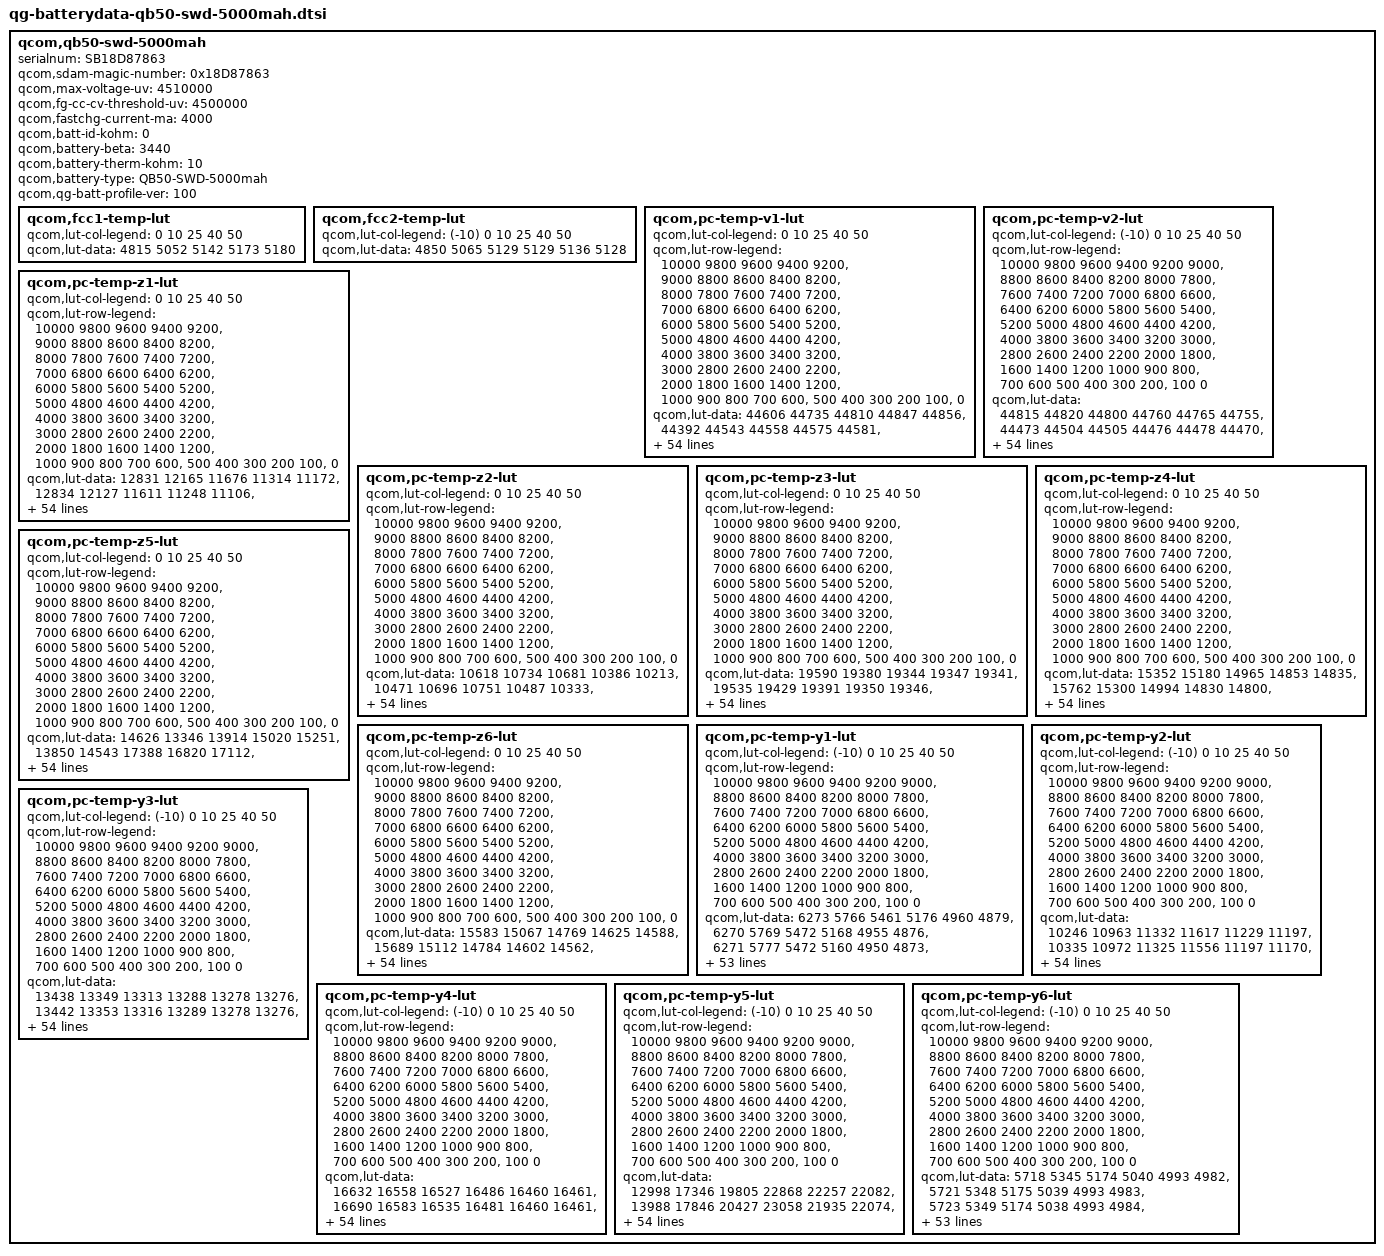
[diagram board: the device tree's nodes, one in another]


qcom,qb50-swd-5000mah {
    /* 6559013_Heyuan_P562A_5000mAH_PM7250B_averaged_MasterSlave_Apr24th2023 */
    serialnum = "SB18D87863";
    qcom,sdam-magic-number = <0x18D87863>;
    qcom,max-voltage-uv = <4510000>;
    qcom,fg-cc-cv-threshold-uv = <4500000>;
    qcom,fastchg-current-ma = <4000>;
    qcom,batt-id-kohm = <0>;
    qcom,battery-beta = <3440>;
    qcom,battery-therm-kohm = <10>;
    qcom,battery-type = "QB50-SWD-5000mah";
    qcom,qg-batt-profile-ver = <100>;

	qcom,fcc1-temp-lut {
		qcom,lut-col-legend = <0 10 25 40 50>;
		qcom,lut-data = <4815 5052 5142 5173 5180>;
	};

	qcom,fcc2-temp-lut {
		qcom,lut-col-legend = <(-10) 0 10 25 40 50>;
		qcom,lut-data = <4850 5065 5129 5129 5136 5128>;
	};

	qcom,pc-temp-v1-lut {
		qcom,lut-col-legend = <0 10 25 40 50>;
		qcom,lut-row-legend = <10000 9800 9600 9400 9200>,
			<9000 8800 8600 8400 8200>,
			<8000 7800 7600 7400 7200>,
			<7000 6800 6600 6400 6200>,
			<6000 5800 5600 5400 5200>,
			<5000 4800 4600 4400 4200>,
			<4000 3800 3600 3400 3200>,
			<3000 2800 2600 2400 2200>,
			<2000 1800 1600 1400 1200>,
			<1000 900 800 700 600>,
			<500 400 300 200 100>,
			<0>;
		qcom,lut-data = <44606 44735 44810 44847 44856>,
			<44392 44543 44558 44575 44581>,
			<44182 44330 44352 44357 44362>,
			<43974 44118 44156 44160 44168>,
			<43760 43909 43952 43963 43974>,
			<43541 43696 43738 43755 43765>,
			<43313 43470 43515 43537 43547>,
			<43074 43232 43281 43307 43318>,
			<42828 42985 43035 43065 43078>,
			<42581 42729 42783 42814 42829>,
			<42332 42470 42522 42556 42573>,
			<42086 42214 42259 42294 42313>,
			<41846 41961 42001 42035 42058>,
			<41610 41714 41747 41778 41804>,
			<41381 41471 41500 41527 41555>,
			<41157 41234 41260 41285 41311>,
			<40940 41006 41027 41050 41073>,
			<40731 40787 40803 40825 40844>,
			<40531 40577 40588 40609 40623>,
			<40339 40380 40386 40402 40414>,
			<40160 40187 40201 40215 40224>,
			<39988 39986 39989 40010 40021>,
			<39813 39782 39706 39737 39758>,
			<39635 39562 39423 39446 39476>,
			<39450 39294 39226 39245 39276>,
			<39247 39052 39073 39098 39130>,
			<39043 38914 38945 38969 38994>,
			<38883 38818 38839 38849 38853>,
			<38756 38727 38743 38737 38721>,
			<38650 38635 38646 38628 38611>,
			<38564 38550 38554 38525 38517>,
			<38492 38471 38466 38432 38428>,
			<38427 38398 38383 38349 38345>,
			<38368 38330 38306 38273 38267>,
			<38314 38268 38239 38203 38194>,
			<38267 38211 38178 38139 38125>,
			<38226 38162 38117 38073 38052>,
			<38183 38118 38060 38009 37975>,
			<38135 38057 37990 37932 37887>,
			<38081 37970 37898 37828 37775>,
			<38006 37864 37788 37705 37647>,
			<37886 37743 37666 37581 37517>,
			<37755 37601 37525 37449 37381>,
			<37617 37433 37359 37287 37212>,
			<37458 37274 37202 37140 37065>,
			<37294 37165 37098 37048 36989>,
			<37229 37129 37064 37013 36962>,
			<37189 37099 37043 36991 36936>,
			<37139 37076 37020 36970 36914>,
			<37097 37042 36971 36914 36852>,
			<37058 36872 36749 36656 36580>,
			<37005 36452 36313 36208 36135>,
			<36855 35867 35715 35618 35551>,
			<36413 35046 34884 34808 34751>,
			<35577 33700 33581 33539 33506>,
			<30000 30000 30000 30000 30000>;
	};

	qcom,pc-temp-v2-lut {
		qcom,lut-col-legend = <(-10) 0 10 25 40 50>;
		qcom,lut-row-legend = <10000 9800 9600 9400 9200 9000>,
			<8800 8600 8400 8200 8000 7800>,
			<7600 7400 7200 7000 6800 6600>,
			<6400 6200 6000 5800 5600 5400>,
			<5200 5000 4800 4600 4400 4200>,
			<4000 3800 3600 3400 3200 3000>,
			<2800 2600 2400 2200 2000 1800>,
			<1600 1400 1200 1000 900 800>,
			<700 600 500 400 300 200>,
			<100 0>;
		qcom,lut-data = <44815 44820 44800 44760 44765 44755>,
			<44473 44504 44505 44476 44478 44470>,
			<44172 44224 44240 44215 44215 44210>,
			<43921 43987 44011 43984 43983 43980>,
			<43718 43789 43813 43779 43778 43776>,
			<43521 43588 43609 43568 43568 43568>,
			<43309 43367 43386 43341 43343 43343>,
			<43090 43138 43153 43105 43110 43111>,
			<42865 42900 42909 42860 42867 42870>,
			<42629 42651 42651 42605 42614 42619>,
			<42388 42399 42392 42348 42358 42365>,
			<42142 42146 42133 42088 42099 42107>,
			<41889 41893 41875 41831 41842 41851>,
			<41635 41648 41621 41578 41590 41600>,
			<41382 41410 41372 41330 41342 41353>,
			<41129 41167 41131 41089 41103 41114>,
			<40874 40918 40902 40855 40870 40881>,
			<40617 40663 40674 40629 40645 40655>,
			<40365 40394 40444 40417 40431 40440>,
			<40119 40115 40208 40209 40223 40233>,
			<39879 39856 39950 39987 40017 40030>,
			<39653 39617 39670 39745 39814 39833>,
			<39437 39395 39415 39505 39597 39620>,
			<39234 39194 39200 39264 39335 39358>,
			<39050 39009 39008 39041 39081 39099>,
			<38880 38842 38841 38865 38900 38916>,
			<38713 38691 38693 38720 38756 38772>,
			<38542 38550 38557 38590 38627 38643>,
			<38387 38418 38432 38473 38508 38522>,
			<38263 38294 38317 38365 38401 38412>,
			<38157 38180 38211 38265 38304 38314>,
			<38064 38070 38113 38171 38216 38223>,
			<37986 37976 38022 38086 38135 38140>,
			<37917 37900 37937 38010 38060 38065>,
			<37848 37835 37860 37937 37982 37986>,
			<37782 37777 37797 37865 37894 37888>,
			<37715 37725 37739 37794 37799 37778>,
			<37643 37670 37679 37713 37700 37666>,
			<37569 37604 37615 37624 37598 37556>,
			<37490 37526 37541 37530 37495 37449>,
			<37407 37427 37443 37435 37399 37350>,
			<37319 37297 37322 37330 37295 37246>,
			<37229 37161 37179 37201 37169 37124>,
			<37137 37018 37007 37051 37025 36974>,
			<37048 36872 36828 36918 36906 36854>,
			<36960 36738 36716 36860 36862 36811>,
			<36916 36679 36661 36840 36851 36799>,
			<36875 36619 36595 36819 36834 36782>,
			<36828 36534 36508 36783 36807 36754>,
			<36770 36392 36366 36696 36726 36668>,
			<36693 36182 36028 36399 36413 36339>,
			<36602 35947 35361 35874 35904 35836>,
			<36502 35705 34564 35163 35233 35171>,
			<36175 35395 33682 34163 34291 34247>,
			<36109 34856 32472 32640 32894 32858>,
			<36125 34125 29462 28844 28234 28930>;
	};

	qcom,pc-temp-z1-lut {
		qcom,lut-col-legend = <0 10 25 40 50>;
		qcom,lut-row-legend = <10000 9800 9600 9400 9200>,
			<9000 8800 8600 8400 8200>,
			<8000 7800 7600 7400 7200>,
			<7000 6800 6600 6400 6200>,
			<6000 5800 5600 5400 5200>,
			<5000 4800 4600 4400 4200>,
			<4000 3800 3600 3400 3200>,
			<3000 2800 2600 2400 2200>,
			<2000 1800 1600 1400 1200>,
			<1000 900 800 700 600>,
			<500 400 300 200 100>,
			<0>;
		qcom,lut-data = <12831 12165 11676 11314 11172>,
			<12834 12127 11611 11248 11106>,
			<12819 12096 11589 11225 11083>,
			<12785 12072 11558 11204 11072>,
			<12757 12045 11530 11186 11059>,
			<12729 12018 11508 11171 11049>,
			<12703 11993 11487 11158 11041>,
			<12677 11972 11469 11148 11034>,
			<12646 11954 11454 11139 11029>,
			<12608 11935 11442 11132 11026>,
			<12558 11912 11430 11128 11024>,
			<12519 11892 11421 11125 11023>,
			<12503 11874 11418 11122 11022>,
			<12491 11864 11416 11120 11021>,
			<12481 11861 11414 11118 11021>,
			<12455 11859 11411 11117 11021>,
			<12431 11858 11409 11117 11021>,
			<12428 11860 11408 11117 11022>,
			<12433 11862 11407 11119 11023>,
			<12438 11864 11408 11121 11025>,
			<12452 11866 11413 11123 11026>,
			<12466 11868 11415 11124 11027>,
			<12466 11872 11414 11124 11028>,
			<12466 11878 11412 11124 11029>,
			<12467 11886 11415 11125 11031>,
			<12472 11892 11422 11129 11034>,
			<12477 11894 11428 11133 11037>,
			<12483 11895 11432 11137 11040>,
			<12488 11896 11435 11141 11043>,
			<12494 11901 11441 11145 11046>,
			<12502 11908 11447 11149 11050>,
			<12515 11915 11454 11153 11053>,
			<12523 11923 11459 11158 11056>,
			<12525 11931 11465 11163 11059>,
			<12526 11939 11474 11168 11063>,
			<12530 11948 11485 11173 11068>,
			<12539 11959 11492 11180 11073>,
			<12552 11972 11496 11187 11077>,
			<12568 11987 11502 11195 11082>,
			<12587 12007 11513 11200 11087>,
			<12601 12024 11526 11206 11092>,
			<12611 12032 11537 11213 11098>,
			<12630 12039 11547 11220 11102>,
			<12674 12046 11549 11225 11105>,
			<12675 12062 11554 11230 11107>,
			<12713 12070 11570 11236 11112>,
			<12703 12067 11572 11237 11112>,
			<12737 12055 11568 11238 11113>,
			<12719 12057 11572 11243 11115>,
			<12698 12081 11577 11247 11120>,
			<12709 12084 11586 11255 11125>,
			<12728 12095 11596 11259 11129>,
			<12750 12128 11613 11269 11137>,
			<12761 12139 11631 11286 11148>,
			<12761 12139 11631 11286 11148>,
			<12761 12139 11631 11286 11148>;
	};

	qcom,pc-temp-z2-lut {
		qcom,lut-col-legend = <0 10 25 40 50>;
		qcom,lut-row-legend = <10000 9800 9600 9400 9200>,
			<9000 8800 8600 8400 8200>,
			<8000 7800 7600 7400 7200>,
			<7000 6800 6600 6400 6200>,
			<6000 5800 5600 5400 5200>,
			<5000 4800 4600 4400 4200>,
			<4000 3800 3600 3400 3200>,
			<3000 2800 2600 2400 2200>,
			<2000 1800 1600 1400 1200>,
			<1000 900 800 700 600>,
			<500 400 300 200 100>,
			<0>;
		qcom,lut-data = <10618 10734 10681 10386 10213>,
			<10471 10696 10751 10487 10333>,
			<10481 10696 10798 10720 10479>,
			<10485 10692 10774 10704 10541>,
			<10476 10662 10739 10662 10567>,
			<10449 10605 10691 10619 10559>,
			<10425 10561 10641 10565 10537>,
			<10410 10528 10592 10523 10512>,
			<10397 10502 10540 10483 10478>,
			<10386 10478 10517 10468 10460>,
			<10374 10461 10517 10467 10468>,
			<10367 10461 10521 10467 10477>,
			<10364 10474 10526 10470 10464>,
			<10364 10490 10529 10478 10431>,
			<10366 10503 10531 10486 10418>,
			<10380 10517 10538 10483 10432>,
			<10399 10532 10549 10469 10443>,
			<10410 10550 10561 10452 10429>,
			<10419 10568 10574 10431 10391>,
			<10432 10585 10586 10426 10370>,
			<10514 10603 10597 10426 10361>,
			<10639 10623 10617 10428 10360>,
			<10664 10644 10691 10542 10485>,
			<10576 10651 10763 10728 10686>,
			<10502 10636 10719 10717 10694>,
			<10510 10613 10582 10508 10551>,
			<10525 10609 10534 10400 10480>,
			<10531 10619 10563 10516 10778>,
			<10534 10626 10601 10670 11141>,
			<10536 10628 10633 10742 11077>,
			<10540 10630 10662 10793 10762>,
			<10545 10632 10675 10799 10557>,
			<10549 10636 10681 10702 10460>,
			<10553 10642 10684 10587 10391>,
			<10557 10650 10674 10515 10334>,
			<10560 10658 10660 10456 10292>,
			<10563 10666 10663 10441 10294>,
			<10568 10673 10681 10440 10360>,
			<10574 10682 10699 10448 10429>,
			<10582 10697 10728 10541 10478>,
			<10592 10708 10756 10654 10516>,
			<10603 10709 10763 10663 10533>,
			<10623 10710 10766 10652 10545>,
			<10676 10711 10766 10666 10612>,
			<10974 10794 10789 10674 10650>,
			<10942 10931 10838 10600 10511>,
			<10949 10970 10819 10602 10498>,
			<10748 10973 10760 10602 10499>,
			<10672 11458 10779 10608 10552>,
			<10567 11840 10840 10755 10657>,
			<10451 11407 10854 10625 10534>,
			<10208 11167 10844 10448 10302>,
			<10125 10909 10737 10349 10238>,
			<10302 10600 10599 10309 10170>,
			<10302 10600 10599 10309 10170>,
			<10302 10600 10599 10309 10170>;
	};

	qcom,pc-temp-z3-lut {
		qcom,lut-col-legend = <0 10 25 40 50>;
		qcom,lut-row-legend = <10000 9800 9600 9400 9200>,
			<9000 8800 8600 8400 8200>,
			<8000 7800 7600 7400 7200>,
			<7000 6800 6600 6400 6200>,
			<6000 5800 5600 5400 5200>,
			<5000 4800 4600 4400 4200>,
			<4000 3800 3600 3400 3200>,
			<3000 2800 2600 2400 2200>,
			<2000 1800 1600 1400 1200>,
			<1000 900 800 700 600>,
			<500 400 300 200 100>,
			<0>;
		qcom,lut-data = <19590 19380 19344 19347 19341>,
			<19535 19429 19391 19350 19346>,
			<19601 19490 19417 19385 19371>,
			<19649 19520 19427 19394 19378>,
			<19665 19530 19433 19399 19383>,
			<19676 19536 19440 19403 19388>,
			<19681 19539 19445 19406 19394>,
			<19680 19540 19446 19408 19398>,
			<19677 19539 19445 19408 19399>,
			<19673 19538 19443 19407 19398>,
			<19667 19536 19440 19404 19396>,
			<19661 19530 19437 19401 19392>,
			<19657 19518 19433 19398 19388>,
			<19651 19508 19429 19396 19384>,
			<19644 19503 19424 19393 19379>,
			<19636 19500 19419 19389 19376>,
			<19628 19496 19415 19384 19372>,
			<19622 19493 19412 19379 19369>,
			<19615 19490 19409 19374 19365>,
			<19611 19486 19406 19369 19361>,
			<19613 19483 19402 19364 19356>,
			<19618 19484 19400 19361 19353>,
			<19618 19488 19409 19365 19354>,
			<19611 19492 19420 19371 19356>,
			<19605 19497 19415 19368 19353>,
			<19610 19501 19400 19349 19337>,
			<19620 19499 19392 19340 19328>,
			<19623 19493 19389 19347 19365>,
			<19621 19490 19388 19360 19410>,
			<19618 19488 19390 19376 19412>,
			<19615 19486 19395 19394 19403>,
			<19611 19486 19401 19400 19394>,
			<19607 19485 19409 19396 19386>,
			<19604 19485 19413 19389 19378>,
			<19600 19486 19412 19382 19367>,
			<19597 19487 19409 19373 19356>,
			<19594 19486 19406 19364 19349>,
			<19591 19483 19402 19355 19342>,
			<19584 19480 19398 19350 19339>,
			<19577 19478 19396 19351 19337>,
			<19572 19475 19394 19352 19337>,
			<19570 19472 19391 19352 19338>,
			<19565 19467 19387 19351 19344>,
			<19537 19464 19386 19353 19351>,
			<19424 19450 19383 19353 19353>,
			<19419 19418 19370 19341 19342>,
			<19432 19407 19368 19339 19328>,
			<19312 19403 19353 19334 19323>,
			<19311 19318 19352 19331 19314>,
			<19304 19288 19346 19317 19310>,
			<19296 19317 19343 19340 19336>,
			<19284 19325 19340 19359 19350>,
			<19288 19334 19341 19361 19352>,
			<19350 19399 19377 19355 19350>,
			<19350 19399 19377 19355 19350>,
			<19350 19399 19377 19355 19350>;
	};

	qcom,pc-temp-z4-lut {
		qcom,lut-col-legend = <0 10 25 40 50>;
		qcom,lut-row-legend = <10000 9800 9600 9400 9200>,
			<9000 8800 8600 8400 8200>,
			<8000 7800 7600 7400 7200>,
			<7000 6800 6600 6400 6200>,
			<6000 5800 5600 5400 5200>,
			<5000 4800 4600 4400 4200>,
			<4000 3800 3600 3400 3200>,
			<3000 2800 2600 2400 2200>,
			<2000 1800 1600 1400 1200>,
			<1000 900 800 700 600>,
			<500 400 300 200 100>,
			<0>;
		qcom,lut-data = <15352 15180 14965 14853 14835>,
			<15762 15300 14994 14830 14800>,
			<15666 15242 15042 14901 14863>,
			<15512 15153 14979 14872 14844>,
			<15381 15064 14916 14835 14815>,
			<15256 14979 14872 14808 14793>,
			<15156 14917 14833 14785 14774>,
			<15080 14869 14802 14763 14755>,
			<15019 14831 14777 14742 14735>,
			<14968 14799 14755 14727 14723>,
			<14923 14774 14734 14719 14719>,
			<14885 14754 14719 14713 14716>,
			<14854 14740 14711 14708 14714>,
			<14827 14730 14706 14702 14711>,
			<14804 14723 14701 14698 14707>,
			<14781 14717 14697 14694 14704>,
			<14763 14712 14692 14691 14700>,
			<14755 14707 14688 14687 14697>,
			<14751 14703 14683 14684 14694>,
			<14745 14699 14679 14679 14690>,
			<14729 14696 14674 14674 14684>,
			<14709 14697 14674 14671 14681>,
			<14705 14703 14716 14708 14714>,
			<14716 14715 14774 14773 14775>,
			<14730 14765 14801 14800 14798>,
			<14752 14815 14819 14814 14806>,
			<14780 14814 14822 14817 14808>,
			<14792 14796 14810 14800 14762>,
			<14797 14780 14791 14770 14704>,
			<14800 14766 14773 14741 14692>,
			<14797 14754 14754 14709 14689>,
			<14789 14743 14736 14692 14686>,
			<14781 14733 14718 14685 14681>,
			<14774 14725 14704 14680 14677>,
			<14766 14718 14695 14676 14673>,
			<14758 14712 14688 14673 14669>,
			<14749 14706 14685 14670 14666>,
			<14739 14700 14682 14668 14664>,
			<14728 14696 14681 14668 14663>,
			<14716 14694 14684 14676 14674>,
			<14707 14692 14688 14686 14689>,
			<14700 14687 14687 14686 14687>,
			<14697 14680 14683 14681 14678>,
			<14698 14675 14680 14681 14680>,
			<14754 14662 14671 14678 14678>,
			<14742 14659 14654 14659 14654>,
			<14729 14663 14649 14655 14657>,
			<14863 14661 14651 14646 14650>,
			<14862 14753 14640 14628 14635>,
			<14868 14780 14640 14631 14626>,
			<14873 14751 14662 14645 14646>,
			<14884 14761 14681 14646 14655>,
			<14883 14761 14686 14651 14661>,
			<14858 14712 14658 14662 14671>,
			<14858 14712 14658 14662 14671>,
			<14858 14712 14658 14662 14671>;
	};

	qcom,pc-temp-z5-lut {
		qcom,lut-col-legend = <0 10 25 40 50>;
		qcom,lut-row-legend = <10000 9800 9600 9400 9200>,
			<9000 8800 8600 8400 8200>,
			<8000 7800 7600 7400 7200>,
			<7000 6800 6600 6400 6200>,
			<6000 5800 5600 5400 5200>,
			<5000 4800 4600 4400 4200>,
			<4000 3800 3600 3400 3200>,
			<3000 2800 2600 2400 2200>,
			<2000 1800 1600 1400 1200>,
			<1000 900 800 700 600>,
			<500 400 300 200 100>,
			<0>;
		qcom,lut-data = <14626 13346 13914 15020 15251>,
			<13850 14543 17388 16820 17112>,
			<14944 16642 17854 19397 19650>,
			<15934 18064 18570 20390 20608>,
			<16591 18822 19410 21247 21559>,
			<17185 19474 20232 21880 22756>,
			<17777 20242 21078 22454 24131>,
			<18368 21082 21711 23269 25667>,
			<18908 21961 22236 24447 27481>,
			<19413 23115 22973 25591 28846>,
			<20085 24268 24563 26459 29615>,
			<20858 24831 26190 27287 30069>,
			<21662 25099 26991 28342 30086>,
			<22550 25397 27504 29651 29962>,
			<23603 25945 27579 30613 29988>,
			<25163 26852 27940 31256 30685>,
			<26731 27887 28536 31528 31777>,
			<27733 29082 29714 31498 32826>,
			<28451 30286 31252 31822 33979>,
			<29434 31305 32445 32486 35248>,
			<31826 32539 33463 33618 36938>,
			<35039 35695 35474 34727 37971>,
			<36912 41458 44393 36131 37136>,
			<38374 45161 53601 37665 34925>,
			<40332 46947 49350 35494 30834>,
			<46637 47957 34389 24735 22004>,
			<55992 45659 26417 19060 17632>,
			<58578 39119 23823 19307 26884>,
			<55847 35358 22635 19884 38212>,
			<52192 33904 22836 22638 38978>,
			<49217 33151 23609 29263 37804>,
			<46261 33375 25169 33713 37178>,
			<44061 34307 29377 36471 37327>,
			<42446 35650 33453 37848 37354>,
			<41201 38336 36171 37309 35434>,
			<40542 40784 38316 36045 32381>,
			<40135 41733 39357 34655 31742>,
			<39723 42338 40033 32439 31790>,
			<38863 42676 40238 31289 31817>,
			<37802 43661 39678 32431 30814>,
			<37878 44496 38494 33832 29416>,
			<40849 42202 35670 32258 29350>,
			<41170 38953 31685 27870 29964>,
			<30371 38907 31669 28892 33772>,
			<21222 38624 32978 29782 37021>,
			<23446 29605 31084 24948 29747>,
			<24563 24905 29708 24381 21139>,
			<12648 23103 23109 23492 20692>,
			<12569 13598 23625 26751 20474>,
			<12328 12303 22296 21114 21253>,
			<12117 13458 19923 26867 28842>,
			<11889 13488 16936 28165 26035>,
			<11942 13645 16434 25375 22283>,
			<13573 21627 23301 19590 18027>,
			<13573 21627 23301 19590 18027>,
			<13573 21627 23301 19590 18027>;
	};

	qcom,pc-temp-z6-lut {
		qcom,lut-col-legend = <0 10 25 40 50>;
		qcom,lut-row-legend = <10000 9800 9600 9400 9200>,
			<9000 8800 8600 8400 8200>,
			<8000 7800 7600 7400 7200>,
			<7000 6800 6600 6400 6200>,
			<6000 5800 5600 5400 5200>,
			<5000 4800 4600 4400 4200>,
			<4000 3800 3600 3400 3200>,
			<3000 2800 2600 2400 2200>,
			<2000 1800 1600 1400 1200>,
			<1000 900 800 700 600>,
			<500 400 300 200 100>,
			<0>;
		qcom,lut-data = <15583 15067 14769 14625 14588>,
			<15689 15112 14784 14602 14562>,
			<15638 15089 14806 14645 14598>,
			<15555 15049 14776 14633 14590>,
			<15479 15001 14745 14618 14579>,
			<15403 14951 14723 14606 14572>,
			<15339 14915 14703 14596 14566>,
			<15286 14885 14686 14586 14560>,
			<15240 14859 14669 14576 14552>,
			<15198 14836 14655 14568 14545>,
			<15160 14816 14643 14562 14541>,
			<15127 14798 14632 14557 14538>,
			<15099 14782 14625 14553 14534>,
			<15074 14770 14620 14548 14530>,
			<15052 14763 14614 14544 14526>,
			<15030 14758 14609 14540 14522>,
			<15014 14754 14604 14535 14518>,
			<15006 14749 14600 14531 14515>,
			<15001 14746 14597 14527 14512>,
			<14997 14742 14593 14523 14508>,
			<14994 14740 14590 14518 14502>,
			<14991 14741 14590 14515 14499>,
			<14991 14747 14614 14535 14515>,
			<14994 14756 14644 14566 14543>,
			<15000 14782 14650 14572 14549>,
			<15013 14805 14652 14571 14545>,
			<15033 14805 14652 14569 14543>,
			<15042 14797 14646 14565 14543>,
			<15046 14790 14638 14560 14543>,
			<15048 14785 14633 14557 14540>,
			<15047 14781 14628 14554 14534>,
			<15045 14778 14625 14551 14528>,
			<15043 14775 14623 14546 14523>,
			<15040 14774 14621 14541 14518>,
			<15038 14774 14618 14536 14511>,
			<15037 14774 14615 14531 14504>,
			<15035 14774 14614 14526 14499>,
			<15035 14774 14612 14521 14494>,
			<15035 14774 14612 14519 14493>,
			<15037 14777 14615 14524 14497>,
			<15039 14780 14618 14529 14503>,
			<15048 14781 14618 14530 14504>,
			<15053 14782 14617 14529 14504>,
			<15054 14784 14618 14531 14508>,
			<15039 14779 14616 14530 14510>,
			<15041 14767 14605 14517 14494>,
			<15043 14765 14602 14515 14489>,
			<15041 14762 14597 14508 14482>,
			<15042 14759 14592 14499 14472>,
			<15042 14760 14591 14495 14466>,
			<15043 14768 14602 14513 14489>,
			<15049 14782 14613 14526 14503>,
			<15063 14795 14621 14532 14509>,
			<15092 14819 14636 14537 14515>,
			<15092 14819 14636 14537 14515>,
			<15092 14819 14636 14537 14515>;
	};

	qcom,pc-temp-y1-lut {
		qcom,lut-col-legend = <(-10) 0 10 25 40 50>;
		qcom,lut-row-legend = <10000 9800 9600 9400 9200 9000>,
			<8800 8600 8400 8200 8000 7800>,
			<7600 7400 7200 7000 6800 6600>,
			<6400 6200 6000 5800 5600 5400>,
			<5200 5000 4800 4600 4400 4200>,
			<4000 3800 3600 3400 3200 3000>,
			<2800 2600 2400 2200 2000 1800>,
			<1600 1400 1200 1000 900 800>,
			<700 600 500 400 300 200>,
			<100 0>;
		qcom,lut-data = <6273 5766 5461 5176 4960 4879>,
			<6270 5769 5472 5168 4955 4876>,
			<6271 5777 5472 5160 4950 4873>,
			<6275 5787 5467 5152 4946 4869>,
			<6279 5796 5460 5145 4941 4866>,
			<6282 5799 5458 5141 4937 4864>,
			<6285 5799 5454 5139 4933 4860>,
			<6290 5800 5448 5137 4929 4858>,
			<6291 5797 5444 5133 4926 4857>,
			<6283 5786 5439 5127 4923 4856>,
			<6274 5780 5436 5121 4920 4855>,
			<6273 5779 5435 5117 4918 4854>,
			<6274 5780 5434 5113 4916 4854>,
			<6275 5780 5433 5108 4915 4853>,
			<6272 5782 5432 5104 4914 4853>,
			<6269 5782 5431 5104 4913 4853>,
			<6263 5785 5427 5105 4913 4854>,
			<6257 5788 5423 5106 4913 4855>,
			<6255 5788 5425 5106 4913 4855>,
			<6259 5786 5429 5106 4914 4855>,
			<6268 5786 5428 5107 4915 4855>,
			<6277 5780 5420 5108 4916 4856>,
			<6289 5773 5416 5109 4917 4858>,
			<6298 5775 5419 5111 4919 4859>,
			<6302 5782 5424 5114 4921 4860>,
			<6305 5786 5427 5117 4924 4862>,
			<6304 5788 5430 5120 4925 4864>,
			<6284 5789 5433 5124 4927 4865>,
			<6266 5788 5442 5128 4930 4866>,
			<6264 5784 5450 5133 4932 4868>,
			<6256 5785 5450 5138 4936 4871>,
			<6251 5792 5447 5144 4939 4875>,
			<6256 5799 5446 5147 4942 4877>,
			<6264 5807 5445 5149 4946 4879>,
			<6266 5813 5446 5152 4949 4881>,
			<6265 5813 5449 5156 4952 4883>,
			<6264 5810 5457 5160 4954 4885>,
			<6265 5809 5463 5163 4956 4887>,
			<6266 5807 5467 5166 4958 4889>,
			<6267 5803 5470 5170 4960 4891>,
			<6261 5804 5473 5174 4962 4892>,
			<6254 5813 5477 5176 4965 4894>,
			<6258 5816 5488 5178 4967 4896>,
			<6276 5818 5502 5188 4970 4898>,
			<6293 5829 5504 5188 4974 4901>,
			<6310 5853 5511 5192 4979 4905>,
			<6313 5848 5518 5205 4980 4904>,
			<6326 5914 5512 5208 4979 4904>,
			<6411 5969 5527 5208 4981 4908>,
			<6446 6016 5608 5224 4981 4907>,
			<6517 5932 5632 5231 4983 4908>,
			<6559 5914 5614 5241 4988 4913>,
			<6539 5914 5382 5282 4999 4919>,
			<6371 5914 5383 5321 5009 4928>,
			<6371 5914 5383 5321 5009 4928>,
			<6371 5914 5383 5321 5009 4928>;
	};

	qcom,pc-temp-y2-lut {
		qcom,lut-col-legend = <(-10) 0 10 25 40 50>;
		qcom,lut-row-legend = <10000 9800 9600 9400 9200 9000>,
			<8800 8600 8400 8200 8000 7800>,
			<7600 7400 7200 7000 6800 6600>,
			<6400 6200 6000 5800 5600 5400>,
			<5200 5000 4800 4600 4400 4200>,
			<4000 3800 3600 3400 3200 3000>,
			<2800 2600 2400 2200 2000 1800>,
			<1600 1400 1200 1000 900 800>,
			<700 600 500 400 300 200>,
			<100 0>;
		qcom,lut-data = <10246 10963 11332 11617 11229 11197>,
			<10335 10972 11325 11556 11197 11170>,
			<10426 10984 11313 11496 11161 11136>,
			<10512 10997 11296 11438 11124 11099>,
			<10586 11008 11276 11384 11088 11061>,
			<10643 11013 11253 11335 11056 11026>,
			<10681 11015 11224 11283 11021 10986>,
			<10710 11016 11194 11241 10992 10949>,
			<10734 11016 11168 11222 10973 10925>,
			<10753 11018 11144 11206 10953 10907>,
			<10770 11023 11138 11198 10933 10890>,
			<10790 11037 11143 11189 10909 10861>,
			<10812 11057 11153 11181 10893 10840>,
			<10838 11082 11176 11185 10904 10838>,
			<10871 11114 11219 11201 10936 10840>,
			<10907 11148 11257 11224 10969 10846>,
			<10937 11186 11292 11271 11006 10859>,
			<10963 11216 11327 11327 11050 10868>,
			<10984 11224 11369 11394 11105 10891>,
			<11000 11228 11405 11456 11177 10952>,
			<11013 11234 11405 11469 11298 11068>,
			<11026 11255 11387 11460 11507 11332>,
			<11040 11279 11379 11451 11604 11464>,
			<11049 11297 11399 11445 11460 11340>,
			<11050 11314 11434 11439 11275 11175>,
			<11045 11327 11461 11447 11242 11156>,
			<11002 11337 11485 11475 11234 11165>,
			<10694 11346 11498 11502 11235 11175>,
			<10400 11358 11512 11519 11267 11198>,
			<10287 11370 11526 11537 11315 11236>,
			<9963 11371 11538 11563 11359 11267>,
			<9736 11364 11552 11597 11409 11299>,
			<9715 11353 11557 11627 11448 11344>,
			<9704 11327 11554 11657 11516 11428>,
			<9696 11280 11548 11676 11568 11504>,
			<9689 11233 11536 11673 11548 11527>,
			<9684 11185 11517 11657 11499 11514>,
			<9679 11128 11491 11640 11465 11464>,
			<9675 11064 11434 11621 11442 11359>,
			<9672 10972 11355 11605 11418 11282>,
			<9669 10660 11260 11599 11387 11236>,
			<9667 9969 11151 11591 11378 11223>,
			<9665 9745 11021 11549 11404 11273>,
			<9663 9693 10776 11488 11316 11262>,
			<9661 9674 10267 11370 11240 11093>,
			<9658 9662 9938 11313 11172 10949>,
			<9657 9656 9732 11277 11179 10973>,
			<9654 9652 9671 11289 11180 10946>,
			<9652 9649 9657 11288 11188 11032>,
			<9650 9648 9652 11291 11232 11050>,
			<9648 9647 9650 11145 11124 10877>,
			<9647 9647 9649 10898 10967 10843>,
			<9647 9648 9648 10555 10904 10736>,
			<9647 9648 9649 10092 10778 10572>,
			<9647 9648 9649 10092 10778 10572>,
			<9647 9648 9649 10092 10778 10572>;
	};

	qcom,pc-temp-y3-lut {
		qcom,lut-col-legend = <(-10) 0 10 25 40 50>;
		qcom,lut-row-legend = <10000 9800 9600 9400 9200 9000>,
			<8800 8600 8400 8200 8000 7800>,
			<7600 7400 7200 7000 6800 6600>,
			<6400 6200 6000 5800 5600 5400>,
			<5200 5000 4800 4600 4400 4200>,
			<4000 3800 3600 3400 3200 3000>,
			<2800 2600 2400 2200 2000 1800>,
			<1600 1400 1200 1000 900 800>,
			<700 600 500 400 300 200>,
			<100 0>;
		qcom,lut-data = <13438 13349 13313 13288 13278 13276>,
			<13442 13353 13316 13289 13278 13276>,
			<13450 13359 13318 13291 13279 13277>,
			<13458 13364 13321 13292 13280 13278>,
			<13465 13369 13323 13293 13280 13278>,
			<13468 13371 13325 13294 13281 13279>,
			<13468 13372 13327 13295 13282 13280>,
			<13467 13372 13328 13296 13283 13281>,
			<13467 13372 13328 13297 13284 13282>,
			<13465 13372 13329 13298 13285 13283>,
			<13463 13372 13329 13299 13285 13283>,
			<13460 13370 13329 13299 13286 13284>,
			<13457 13368 13329 13299 13286 13284>,
			<13453 13367 13328 13299 13287 13285>,
			<13448 13367 13326 13299 13288 13286>,
			<13443 13367 13326 13300 13289 13287>,
			<13437 13366 13326 13301 13291 13288>,
			<13430 13364 13326 13301 13292 13289>,
			<13423 13360 13325 13300 13293 13289>,
			<13417 13354 13324 13298 13293 13290>,
			<13411 13349 13322 13297 13293 13291>,
			<13405 13346 13317 13297 13292 13291>,
			<13399 13343 13313 13295 13290 13290>,
			<13394 13340 13311 13293 13286 13284>,
			<13390 13338 13309 13291 13281 13278>,
			<13386 13337 13308 13289 13280 13278>,
			<13382 13336 13308 13288 13280 13278>,
			<13377 13335 13307 13288 13280 13278>,
			<13373 13333 13307 13289 13279 13278>,
			<13372 13331 13307 13289 13278 13277>,
			<13372 13329 13306 13289 13278 13277>,
			<13373 13327 13306 13288 13279 13277>,
			<13380 13326 13305 13288 13279 13277>,
			<13390 13325 13305 13288 13280 13278>,
			<13402 13326 13305 13289 13281 13279>,
			<13417 13327 13306 13289 13281 13279>,
			<13436 13332 13306 13289 13281 13279>,
			<13460 13337 13307 13289 13280 13279>,
			<13491 13341 13309 13288 13280 13279>,
			<13530 13345 13310 13287 13280 13279>,
			<13583 13350 13312 13288 13281 13280>,
			<13648 13357 13313 13288 13281 13280>,
			<13724 13373 13317 13288 13280 13280>,
			<13822 13415 13318 13286 13279 13278>,
			<13959 13484 13314 13286 13277 13276>,
			<14178 13716 13341 13289 13283 13282>,
			<14352 14103 13390 13292 13288 13285>,
			<14599 15185 13520 13297 13290 13287>,
			<15191 18133 14031 13301 13292 13289>,
			<16643 27704 15750 13305 13292 13289>,
			<19982 65535 22102 13303 13287 13285>,
			<28174 65535 53371 13308 13286 13285>,
			<52455 65535 65535 13327 13291 13288>,
			<65535 65535 65535 13441 13297 13297>,
			<65535 65535 65535 13441 13297 13297>,
			<65535 65535 65535 13441 13297 13297>;
	};

	qcom,pc-temp-y4-lut {
		qcom,lut-col-legend = <(-10) 0 10 25 40 50>;
		qcom,lut-row-legend = <10000 9800 9600 9400 9200 9000>,
			<8800 8600 8400 8200 8000 7800>,
			<7600 7400 7200 7000 6800 6600>,
			<6400 6200 6000 5800 5600 5400>,
			<5200 5000 4800 4600 4400 4200>,
			<4000 3800 3600 3400 3200 3000>,
			<2800 2600 2400 2200 2000 1800>,
			<1600 1400 1200 1000 900 800>,
			<700 600 500 400 300 200>,
			<100 0>;
		qcom,lut-data = <16632 16558 16527 16486 16460 16461>,
			<16690 16583 16535 16481 16460 16461>,
			<16756 16617 16547 16479 16461 16463>,
			<16821 16651 16560 16478 16461 16464>,
			<16876 16679 16570 16477 16461 16465>,
			<16914 16694 16573 16477 16462 16466>,
			<16934 16700 16572 16478 16462 16466>,
			<16948 16704 16571 16480 16463 16466>,
			<16951 16705 16569 16481 16464 16466>,
			<16951 16706 16566 16483 16465 16466>,
			<16951 16707 16565 16485 16467 16466>,
			<16949 16712 16570 16489 16470 16467>,
			<16942 16722 16577 16495 16473 16468>,
			<16933 16734 16588 16503 16477 16470>,
			<16925 16749 16605 16511 16481 16473>,
			<16915 16755 16624 16521 16485 16477>,
			<16901 16752 16651 16534 16490 16480>,
			<16879 16744 16671 16549 16497 16486>,
			<16854 16725 16675 16577 16508 16493>,
			<16828 16686 16675 16606 16524 16502>,
			<16801 16653 16659 16609 16542 16518>,
			<16775 16625 16601 16591 16565 16544>,
			<16750 16602 16552 16567 16573 16555>,
			<16727 16587 16527 16520 16529 16521>,
			<16706 16574 16510 16476 16474 16473>,
			<16687 16567 16505 16470 16463 16463>,
			<16676 16563 16502 16469 16460 16460>,
			<16663 16559 16501 16468 16460 16459>,
			<16651 16554 16502 16471 16464 16462>,
			<16652 16549 16504 16476 16471 16466>,
			<16667 16543 16506 16482 16479 16473>,
			<16681 16534 16508 16488 16488 16482>,
			<16687 16527 16508 16494 16496 16492>,
			<16691 16531 16505 16502 16504 16503>,
			<16696 16541 16503 16507 16508 16509>,
			<16700 16550 16506 16509 16505 16505>,
			<16704 16561 16513 16508 16497 16495>,
			<16707 16572 16522 16503 16487 16485>,
			<16710 16580 16532 16488 16476 16477>,
			<16710 16587 16538 16480 16470 16474>,
			<16709 16602 16538 16479 16473 16478>,
			<16707 16622 16535 16480 16476 16484>,
			<16711 16625 16529 16480 16474 16482>,
			<16720 16622 16525 16471 16456 16458>,
			<16731 16622 16526 16457 16442 16439>,
			<16745 16632 16548 16471 16456 16462>,
			<16751 16643 16580 16486 16478 16496>,
			<16742 16727 16628 16507 16515 16534>,
			<16786 17157 16698 16539 16551 16571>,
			<16962 19449 17015 16570 16568 16578>,
			<17374 32712 20051 16535 16489 16487>,
			<18394 65535 48869 16526 16473 16476>,
			<22887 65535 65535 16571 16476 16477>,
			<19552 65535 65535 16699 16486 16478>,
			<19552 65535 65535 16699 16486 16478>,
			<19552 65535 65535 16699 16486 16478>;
	};

	qcom,pc-temp-y5-lut {
		qcom,lut-col-legend = <(-10) 0 10 25 40 50>;
		qcom,lut-row-legend = <10000 9800 9600 9400 9200 9000>,
			<8800 8600 8400 8200 8000 7800>,
			<7600 7400 7200 7000 6800 6600>,
			<6400 6200 6000 5800 5600 5400>,
			<5200 5000 4800 4600 4400 4200>,
			<4000 3800 3600 3400 3200 3000>,
			<2800 2600 2400 2200 2000 1800>,
			<1600 1400 1200 1000 900 800>,
			<700 600 500 400 300 200>,
			<100 0>;
		qcom,lut-data = <12998 17346 19805 22868 22257 22082>,
			<13988 17846 20427 23058 21935 22074>,
			<14956 18528 20978 23076 21560 22022>,
			<15872 19219 21414 22953 21179 21933>,
			<16707 19749 21695 22721 20834 21816>,
			<17433 19945 21780 22404 20571 21676>,
			<18066 19890 21684 21634 20389 21337>,
			<18632 19777 21472 20706 20182 20928>,
			<19066 19617 20989 20111 19767 20687>,
			<19408 19322 19998 19504 19055 20500>,
			<19673 19043 19141 19067 18351 20201>,
			<19849 18760 18455 18199 17564 19426>,
			<19974 18545 17846 17299 16933 18674>,
			<20125 18728 17284 16758 16693 18354>,
			<20377 19554 16802 16152 16596 18160>,
			<20676 20516 16745 16018 16629 18144>,
			<20945 21825 17338 15738 16716 17888>,
			<21218 22856 18308 15511 16641 17579>,
			<21425 22962 20321 15673 16280 17108>,
			<21619 22952 22762 16097 15872 16494>,
			<21829 23000 23649 17426 16245 16705>,
			<21910 23318 24061 21256 18771 18186>,
			<21924 23566 24203 23871 20852 19484>,
			<21946 23395 23891 24730 21938 20110>,
			<22117 23059 23495 25225 22608 20569>,
			<22464 23026 23324 24490 22292 20812>,
			<22385 23390 23170 22344 21527 20979>,
			<20182 23598 23103 21486 20570 20947>,
			<17965 23497 23209 21986 18953 19647>,
			<17010 23368 23349 22356 17773 17994>,
			<14796 22957 23478 22082 17758 17325>,
			<13329 21925 23755 21716 17932 16931>,
			<13286 21120 24108 21790 18284 16917>,
			<13323 20628 24562 22358 19477 17819>,
			<13395 20093 24852 23079 20799 19130>,
			<13528 20205 24771 24164 21736 20538>,
			<13635 21824 24625 25340 22428 21866>,
			<13701 23155 24682 25446 22677 22546>,
			<13774 23400 24853 24661 22990 23163>,
			<13818 23512 24905 23897 23185 23466>,
			<13841 22111 24540 23511 22922 22878>,
			<13854 16808 23863 23104 22461 22520>,
			<13662 14892 23371 22522 22150 24512>,
			<13253 14447 21205 21484 22321 24809>,
			<13052 13691 15428 21288 18837 19127>,
			<12891 13252 15267 20078 19522 18388>,
			<12813 13343 14551 19668 19948 17297>,
			<12915 12515 13972 20069 18202 16129>,
			<12441 10739 13470 20152 17557 15803>,
			<11358 9442 11783 19947 17384 15779>,
			<10316 9035 9647 19917 17652 16955>,
			<9699 8885 8905 20438 17838 16302>,
			<9385 8778 8792 18776 18600 16070>,
			<16908 8722 8738 16528 21194 20404>,
			<16908 8722 8738 16528 21194 20404>,
			<16908 8722 8738 16528 21194 20404>;
	};

	qcom,pc-temp-y6-lut {
		qcom,lut-col-legend = <(-10) 0 10 25 40 50>;
		qcom,lut-row-legend = <10000 9800 9600 9400 9200 9000>,
			<8800 8600 8400 8200 8000 7800>,
			<7600 7400 7200 7000 6800 6600>,
			<6400 6200 6000 5800 5600 5400>,
			<5200 5000 4800 4600 4400 4200>,
			<4000 3800 3600 3400 3200 3000>,
			<2800 2600 2400 2200 2000 1800>,
			<1600 1400 1200 1000 900 800>,
			<700 600 500 400 300 200>,
			<100 0>;
		qcom,lut-data = <5718 5345 5174 5040 4993 4982>,
			<5721 5348 5175 5039 4993 4983>,
			<5723 5349 5174 5038 4993 4984>,
			<5724 5349 5173 5037 4993 4984>,
			<5724 5349 5171 5036 4993 4985>,
			<5725 5347 5168 5036 4994 4986>,
			<5723 5343 5165 5036 4994 4986>,
			<5719 5337 5161 5036 4995 4987>,
			<5715 5331 5157 5036 4996 4987>,
			<5709 5326 5152 5036 4996 4988>,
			<5702 5321 5150 5036 4997 4989>,
			<5695 5318 5148 5037 4998 4989>,
			<5689 5315 5147 5038 4999 4990>,
			<5681 5315 5148 5039 5000 4991>,
			<5674 5316 5149 5042 5002 4993>,
			<5665 5317 5152 5045 5004 4994>,
			<5656 5314 5159 5048 5007 4996>,
			<5644 5309 5163 5053 5010 4998>,
			<5633 5300 5164 5060 5013 5001>,
			<5623 5284 5163 5067 5018 5004>,
			<5615 5272 5156 5067 5023 5009>,
			<5608 5263 5136 5062 5028 5016>,
			<5601 5255 5120 5054 5030 5018>,
			<5596 5250 5112 5039 5014 5004>,
			<5594 5247 5107 5025 4995 4986>,
			<5593 5246 5106 5023 4991 4983>,
			<5592 5248 5106 5022 4990 4983>,
			<5590 5249 5106 5022 4990 4983>,
			<5588 5249 5107 5024 4991 4983>,
			<5591 5250 5109 5027 4993 4984>,
			<5601 5252 5111 5029 4995 4986>,
			<5615 5254 5113 5031 4998 4989>,
			<5632 5258 5116 5033 5001 4992>,
			<5653 5265 5117 5037 5005 4996>,
			<5676 5275 5119 5039 5007 4999>,
			<5702 5289 5124 5041 5006 4998>,
			<5732 5308 5130 5041 5004 4995>,
			<5765 5330 5137 5041 5001 4993>,
			<5803 5354 5146 5037 4998 4991>,
			<5848 5381 5156 5035 4997 4990>,
			<5899 5410 5166 5036 4998 4992>,
			<5961 5442 5177 5038 5000 4994>,
			<6034 5490 5194 5039 4999 4993>,
			<6128 5566 5219 5037 4993 4986>,
			<6261 5680 5242 5034 4988 4979>,
			<6473 5949 5341 5044 4998 4991>,
			<6641 6316 5450 5053 5008 5003>,
			<6874 7273 5674 5064 5019 5015>,
			<7427 9649 6205 5079 5031 5027>,
			<8663 17040 7694 5093 5036 5029>,
			<11266 49771 13285 5086 5011 5001>,
			<17296 65535 42895 5101 5006 4998>,
			<34800 65535 65535 5168 5012 5002>,
			<65535 65535 65535 5415 5022 5011>,
			<65535 65535 65535 5415 5022 5011>,
			<65535 65535 65535 5415 5022 5011>;
	};

};
